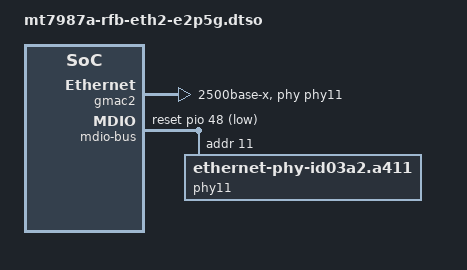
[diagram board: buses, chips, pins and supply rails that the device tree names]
// SPDX-License-Identifier: (GPL-2.0 OR MIT)

/dts-v1/;
/plugin/;

#include <dt-bindings/gpio/gpio.h>

/ {
	fragment@0 {
		target = <&gmac2>;
		__overlay__ {
			phy-handle = <&phy11>;
			phy-mode = "2500base-x";
			status = "okay";
		};
	};

	fragment@1 {
		target-path = "/soc_netsys/ethernet@15100000/mdio-bus";
		__overlay__ {
			reset-gpios = <&pio 48 GPIO_ACTIVE_LOW>;
			reset-delay-us = <10000>;

			phy11: phy@11 {
				compatible = "ethernet-phy-id03a2.a411";
				reg = <11>;
			};
		};
	};
};
